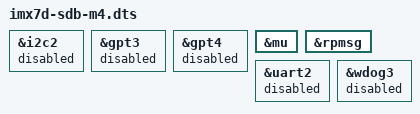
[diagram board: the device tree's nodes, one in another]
/*
 * Copyright (C) 2016 Freescale Semiconductor, Inc.
 *
 * This program is free software; you can redistribute it and/or modify
 * it under the terms of the GNU General Public License version 2 as
 * published by the Free Software Foundation.
 */

#include "imx7d-sdb.dts"

/*
 * The following modules are manupulated by M4, should be disabled
 * at A7/Linux side
 * ADC1/2, FLEXCAN, I2C2, GPT3/4, UART2, WDOG3
 *
 */

&i2c2 {
	status = "disabled";
};

&gpt3 {
	status = "disabled";
};

&gpt4 {
	status = "disabled";
};

&mu{
	status = "okay";
};

&rpmsg{
	status = "okay";
};

&uart2 {
	status = "disabled";
};

&wdog3{
	status = "disabled";
};
